# STM32WB15CCU6 register map
File version: 1.0
Registers are 32-bit, access not given, reset 0x0 unless marked. A register's access mark holds for its fields unless they carry their own. Offsets are from the block's base; [hi:lo] are bit positions; {n}, {i} and the like mark numbered series; 'fields as' and 'values as' point back to an identical list.

## SPI1
Base 0x40013000
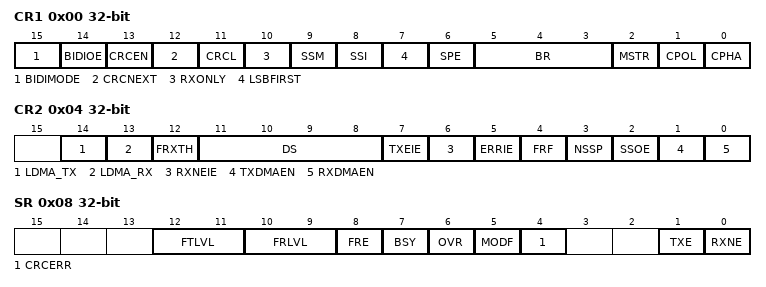
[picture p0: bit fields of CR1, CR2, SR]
0x00 CR1
  [15] BIDIMODE, [14] BIDIOE, [13] CRCEN, [12] CRCNEXT, [11] CRCL, [10] RXONLY, [9] SSM, [8] SSI, [7] LSBFIRST, [6] SPE, [5:3] BR, [2] MSTR, [1] CPOL, [0] CPHA
0x04 CR2
  [14] LDMA_TX, [13] LDMA_RX, [12] FRXTH, [11:8] DS, [7] TXEIE, [6] RXNEIE, [5] ERRIE, [4] FRF, [3] NSSP, [2] SSOE, [1] TXDMAEN, [0] RXDMAEN
0x08 SR
  [12:11] FTLVL, [10:9] FRLVL, [8] FRE, [7] BSY, [6] OVR, [5] MODF, [4] CRCERR, [1] TXE, [0] RXNE
0x0C DR
  [15:0] DR
0x10 CRCPR
  [15:0] CRCPOLY
0x14 RXCRCR
  [15:0] RXCRC
0x18 TXCRCR
  [15:0] TXCRC

## USART1
Base 0x40013800
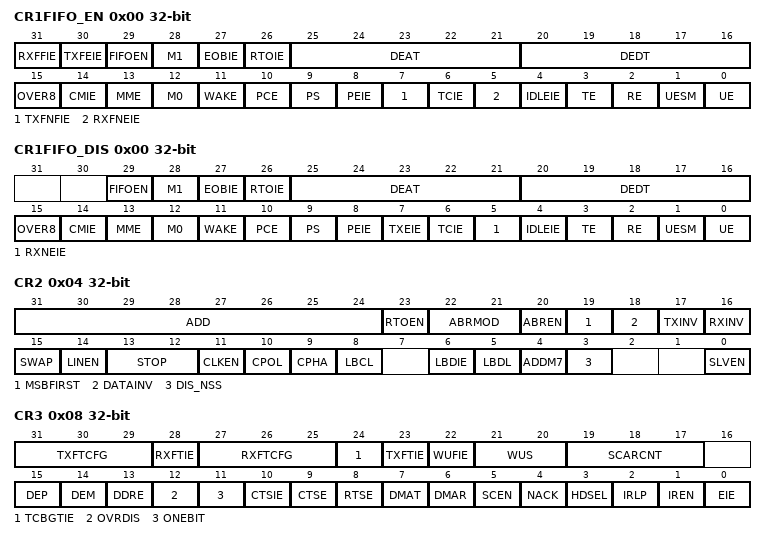
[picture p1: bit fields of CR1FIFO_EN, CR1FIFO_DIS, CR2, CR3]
0x00 CR1FIFO_EN
  [31] RXFFIE, [30] TXFEIE, [29] FIFOEN, [28] M1, [27] EOBIE, [26] RTOIE, [25:21] DEAT, [20:16] DEDT, [15] OVER8, [14] CMIE, [13] MME, [12] M0, [11] WAKE, [10] PCE, [9] PS, [8] PEIE, [7] TXFNFIE, [6] TCIE, [5] RXFNEIE, [4] IDLEIE, [3] TE, [2] RE, [1] UESM, [0] UE
0x00 CR1FIFO_DIS
  [29] FIFOEN, [28] M1, [27] EOBIE, [26] RTOIE, [25:21] DEAT, [20:16] DEDT, [15] OVER8, [14] CMIE, [13] MME, [12] M0, [11] WAKE, [10] PCE, [9] PS, [8] PEIE, [7] TXEIE, [6] TCIE, [5] RXNEIE, [4] IDLEIE, [3] TE, [2] RE, [1] UESM, [0] UE
0x04 CR2
  [31:24] ADD, [23] RTOEN, [22:21] ABRMOD, [20] ABREN, [19] MSBFIRST, [18] DATAINV, [17] TXINV, [16] RXINV, [15] SWAP, [14] LINEN, [13:12] STOP, [11] CLKEN, [10] CPOL, [9] CPHA, [8] LBCL, [6] LBDIE, [5] LBDL, [4] ADDM7, [3] DIS_NSS, [0] SLVEN
0x08 CR3
  [31:29] TXFTCFG, [28] RXFTIE, [27:25] RXFTCFG, [24] TCBGTIE, [23] TXFTIE, [22] WUFIE, [21:20] WUS, [19:17] SCARCNT, [15] DEP, [14] DEM, [13] DDRE, [12] OVRDIS, [11] ONEBIT, [10] CTSIE, [9] CTSE, [8] RTSE, [7] DMAT, [6] DMAR, [5] SCEN, [4] NACK, [3] HDSEL, [2] IRLP, [1] IREN, [0] EIE
0x0C BRR
  [15:0] BRR
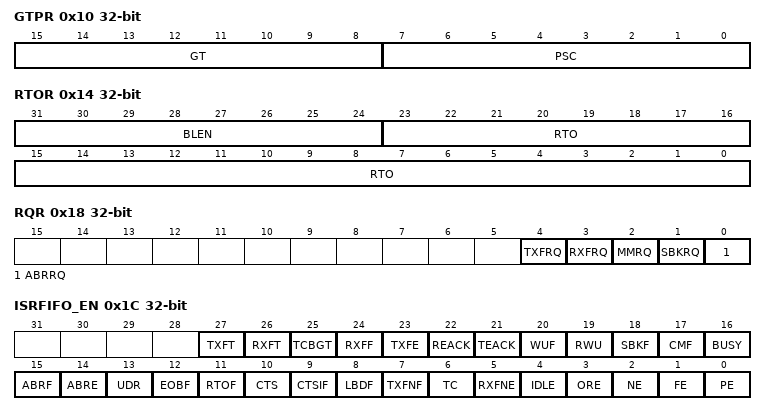
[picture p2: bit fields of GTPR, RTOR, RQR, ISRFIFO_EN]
0x10 GTPR
  [15:8] GT, [7:0] PSC
0x14 RTOR
  [31:24] BLEN, [23:0] RTO
0x18 RQR
  [4] TXFRQ, [3] RXFRQ, [2] MMRQ, [1] SBKRQ, [0] ABRRQ
0x1C ISRFIFO_EN
  [27] TXFT, [26] RXFT, [25] TCBGT, [24] RXFF, [23] TXFE, [22] REACK, [21] TEACK, [20] WUF, [19] RWU, [18] SBKF, [17] CMF, [16] BUSY, [15] ABRF, [14] ABRE, [13] UDR, [12] EOBF, [11] RTOF, [10] CTS, [9] CTSIF, [8] LBDF, [7] TXFNF, [6] TC, [5] RXFNE, [4] IDLE, [3] ORE, [2] NE, [1] FE, [0] PE
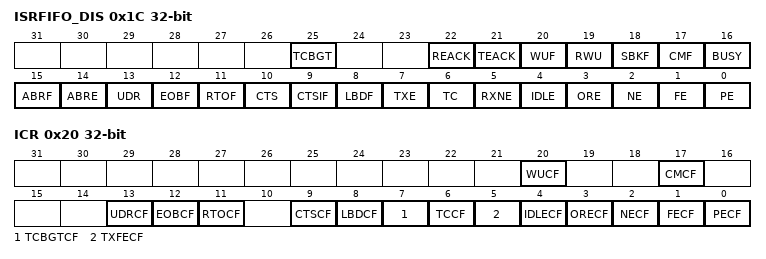
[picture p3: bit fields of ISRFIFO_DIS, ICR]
0x1C ISRFIFO_DIS
  [25] TCBGT, [22] REACK, [21] TEACK, [20] WUF, [19] RWU, [18] SBKF, [17] CMF, [16] BUSY, [15] ABRF, [14] ABRE, [13] UDR, [12] EOBF, [11] RTOF, [10] CTS, [9] CTSIF, [8] LBDF, [7] TXE, [6] TC, [5] RXNE, [4] IDLE, [3] ORE, [2] NE, [1] FE, [0] PE
0x20 ICR
  [20] WUCF, [17] CMCF, [13] UDRCF, [12] EOBCF, [11] RTOCF, [9] CTSCF, [8] LBDCF, [7] TCBGTCF, [6] TCCF, [5] TXFECF, [4] IDLECF, [3] ORECF, [2] NECF, [1] FECF, [0] PECF
0x24 RDR
  [8:0] RDR
0x28 TDR
  [8:0] TDR
0x2C PRESC
  [3:0] PRESCALER

## DMA1
Base 0x40020000
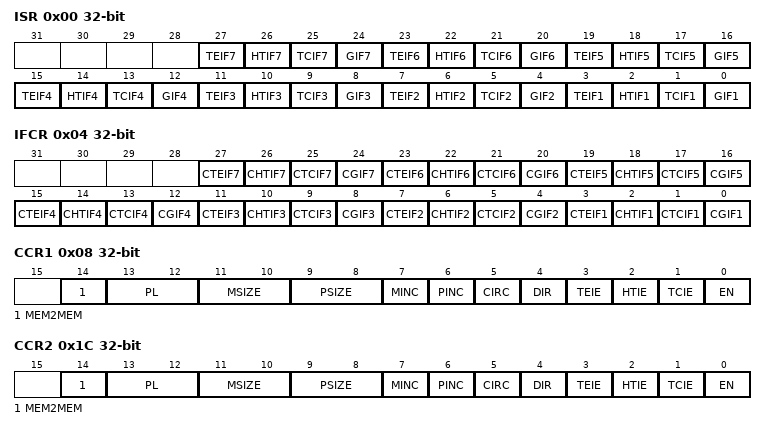
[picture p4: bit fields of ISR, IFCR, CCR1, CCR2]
0x00 ISR
  [4n-1] TEIF{n} (n=1..7), [4n-2] HTIF{n} (n=1..7), [4n-3] TCIF{n} (n=1..7), [4n-4] GIF{n} (n=1..7)
0x04 IFCR
  [4n-1] CTEIF{n} (n=1..7), [4n-2] CHTIF{n} (n=1..7), [4n-3] CTCIF{n} (n=1..7), [4n-4] CGIF{n} (n=1..7)
0x08 CCR1
  [14] MEM2MEM, [13:12] PL, [11:10] MSIZE, [9:8] PSIZE, [7] MINC, [6] PINC, [5] CIRC, [4] DIR, [3] TEIE, [2] HTIE, [1] TCIE, [0] EN
0x0C CNDTR1
  [15:0] NDTR
0x10 CPAR1
  [31:0] PA
{0x0+0x14*i} CMAR{i} (i=1..7)
  [31:0] MA
0x1C CCR2
  fields as CCR1
0x20 CNDTR2
  [15:0] NDTR
0x24 CPAR2
  [31:0] PA
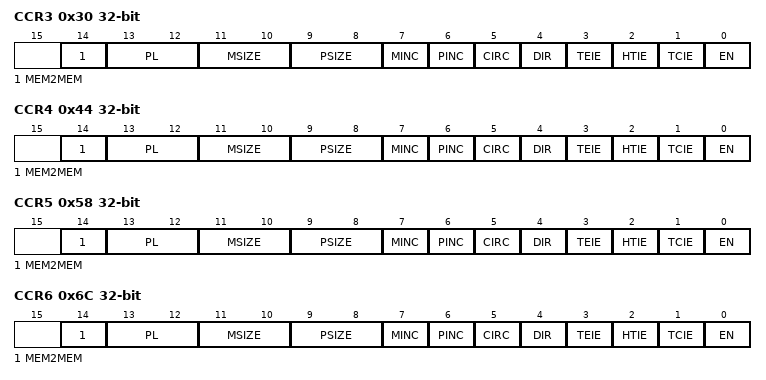
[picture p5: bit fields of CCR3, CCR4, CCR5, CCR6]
0x30 CCR3
  fields as CCR1
0x34 CNDTR3
  [15:0] NDTR
0x38 CPAR3
  [31:0] PA
0x44 CCR4
  fields as CCR1
0x48 CNDTR4
  [15:0] NDTR
0x4C CPAR4
  [31:0] PA
0x58 CCR5
  fields as CCR1
0x5C CNDTR5
  [15:0] NDTR
0x60 CPAR5
  [31:0] PA
0x6C CCR6
  fields as CCR1
0x70 CNDTR6
  [15:0] NDTR
0x74 CPAR6
  [31:0] PA
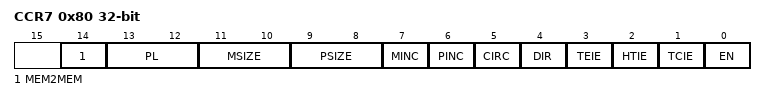
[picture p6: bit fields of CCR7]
0x80 CCR7
  fields as CCR1
0x84 CNDTR7
  [15:0] NDTR
0x88 CPAR7
  [31:0] PA

## DMAMUX
Base 0x40020800
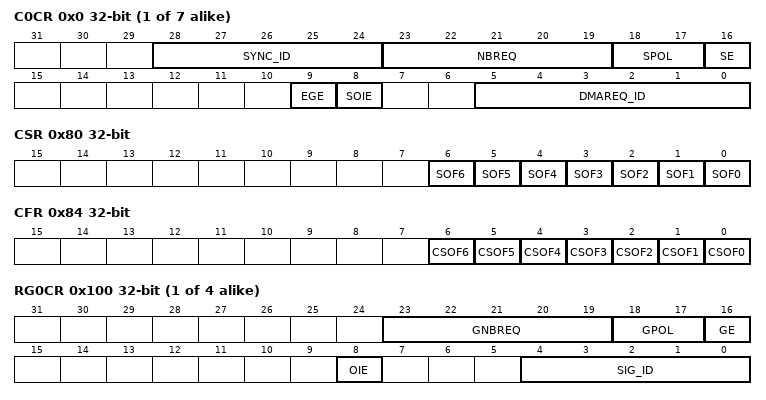
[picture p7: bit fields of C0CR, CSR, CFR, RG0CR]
{0x0+4i} C{i}CR (i=0..6)
  [28:24] SYNC_ID, [23:19] NBREQ, [18:17] SPOL, [16] SE, [9] EGE, [8] SOIE, [5:0] DMAREQ_ID
0x80 CSR
  [n] SOF{n} (n=0..6)
0x84 CFR
  [n] CSOF{n} (n=0..6)
{0x100+4i} RG{i}CR (i=0..3)
  [23:19] GNBREQ, [18:17] GPOL, [16] GE, [8] OIE, [4:0] SIG_ID
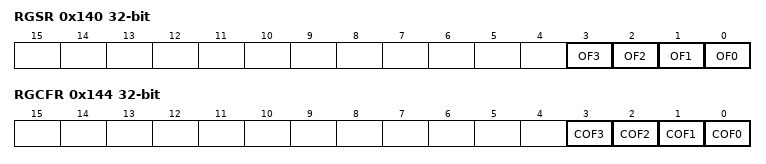
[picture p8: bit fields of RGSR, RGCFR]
0x140 RGSR
  [n] OF{n} (n=0..3)
0x144 RGCFR
  [n] COF{n} (n=0..3)
